VERSION ""

NS_ :

BS_:

BU_: Inverter VCU

BO_ 0 INV_PRIV_NMT: 2 Inverter
 SG_ NodeID  : 8|8@1+ (1,0) [0|255] ""  VCU
 SG_ commmand_specifier  : 0|8@1+ (1,0) [0|255] ""  VCU

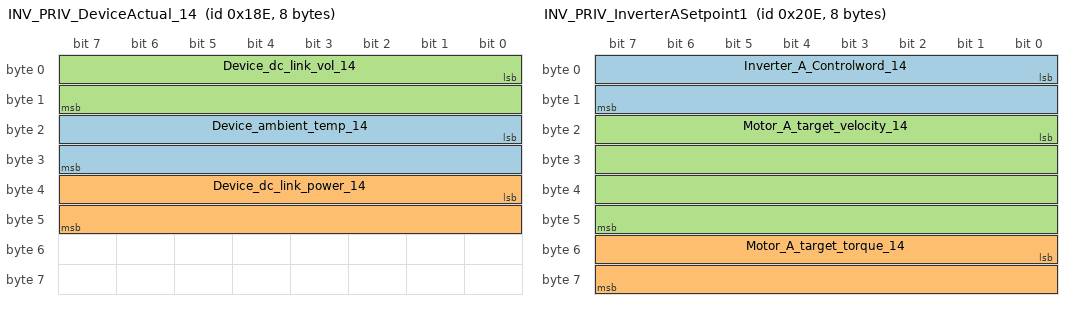
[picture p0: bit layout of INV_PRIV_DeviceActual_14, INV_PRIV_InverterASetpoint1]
BO_ 398 INV_PRIV_DeviceActual_14: 8 Inverter
 SG_ Device_ambient_temp_14  : 16|16@1- (0.0625,0) [-2048|2047.9375] "�C"  VCU
 SG_ Device_dc_link_power_14  : 32|16@1- (0.016,0) [-524.288|524.272] "kW"  VCU
 SG_ Device_dc_link_vol_14  : 0|16@1- (0.0625,0) [-2048|2047.9375] "V"  VCU

BO_ 462 INV_PRIV_InverterAStatus_14: 8 Inverter
 SG_ AMBIENT_OVERTEMPERATURE  : 47|1@1+ (1,0) [0|1] ""  VCU
 SG_ AMBIENT_TEMPERATURE_WARNING  : 46|1@1+ (1,0) [0|1] ""  VCU
 SG_ AMBIENT_TEMPSENSOR_ERROR  : 48|1@1+ (1,0) [0|1] ""  VCU
 SG_ APPC_HAS_GATE_DRIVER_DISABLED  : 44|1@1+ (1,0) [0|1] ""  VCU
 SG_ DCBUS_RIPPLE_TO_HIGH  : 50|1@1+ (1,0) [0|1] ""  VCU
 SG_ DCBUS_SW_OVERVOLTAGE  : 27|1@1+ (1,0) [0|1] ""  VCU
 SG_ DCBUS_SW_UNDERVOLTAGE  : 28|1@1+ (1,0) [0|1] ""  VCU
 SG_ DCBUS_TRIPZONE_OVERVOLTAGE  : 26|1@1+ (1,0) [0|1] ""  VCU
 SG_ EVENTBUFFER_NEW_EVENT  : 16|1@1+ (1,0) [0|1] ""  VCU
 SG_ EVENTBUFFER_OVERFLOW  : 17|1@1+ (1,0) [0|1] ""  VCU
 SG_ INTERLOCK_OPEN  : 43|1@1+ (1,0) [0|1] ""  VCU
 SG_ INVALID_PARAMETER_COMBINATION  : 54|1@1+ (1,0) [0|1] ""  VCU
 SG_ ISOLATION_FAULT  : 58|1@1+ (1,0) [0|1] ""  VCU
 SG_ Inverter_A_Statusword_14  : 0|7@1+ (1,0) [0|127] ""  VCU
 SG_ MOTOR_CONNECTION_TEST_FAILED  : 56|1@1+ (1,0) [0|1] ""  VCU
 SG_ MOTOR_FIELDWEAKENING_ERROR  : 53|1@1+ (1,0) [0|1] ""  VCU
 SG_ MOTOR_I2XT_ERROR  : 52|1@1+ (1,0) [0|1] ""  VCU
 SG_ MOTOR_I2XT_WARNING  : 51|1@1+ (1,0) [0|1] ""  VCU
 SG_ MOTOR_OVERTEMPERATURE  : 32|1@1+ (1,0) [0|1] ""  VCU
 SG_ MOTOR_STALL_ERROR  : 45|1@1+ (1,0) [0|1] ""  VCU
 SG_ MOTOR_STATOR_FREQ_TO_HIGH  : 33|1@1+ (1,0) [0|1] ""  VCU
 SG_ MOTOR_TEMPERATURE_WARNING  : 31|1@1+ (1,0) [0|1] ""  VCU
 SG_ MOTOR_TEMPSENSOR_ERROR  : 30|1@1+ (1,0) [0|1] ""  VCU
 SG_ NEIGHBOUR_FAULT  : 29|1@1+ (1,0) [0|1] ""  VCU
 SG_ NETSYNC_ERROR  : 38|1@1+ (1,0) [0|1] ""  VCU
 SG_ NMT_NOT_OPERATIONAL  : 36|1@1+ (1,0) [0|1] ""  VCU
 SG_ PLUG_COVER_SENSOR_SIGNAL_LOW  : 55|1@1+ (1,0) [0|1] ""  VCU
 SG_ POSDEVICE_SIGNAL_TO_HIGH  : 40|1@1+ (1,0) [0|1] ""  VCU
 SG_ POSDEVICE_SIGNAL_TO_LOW  : 39|1@1+ (1,0) [0|1] ""  VCU
 SG_ POWERMODULE_CLAMPING_TIMEOUT  : 49|1@1+ (1,0) [0|1] ""  VCU
 SG_ POWERMODULE_CURRENT_OFFSET_INI  : 19|1@1+ (1,0) [0|1] ""  VCU
 SG_ POWERMODULE_IXT_FAULT  : 23|1@1+ (1,0) [0|1] ""  VCU
 SG_ POWERMODULE_IXT_WARNING  : 57|1@1+ (1,0) [0|1] ""  VCU
 SG_ POWERMODULE_OVERTEMPERATURE  : 22|1@1+ (1,0) [0|1] ""  VCU
 SG_ POWERMODULE_PATTERNDATA_INCONS  : 25|1@1+ (1,0) [0|1] ""  VCU
 SG_ POWERMODULE_SW_OVERCURRENT  : 24|1@1+ (1,0) [0|1] ""  VCU
 SG_ POWERMODULE_TEMPERATURE_WARNIN  : 21|1@1+ (1,0) [0|1] ""  VCU
 SG_ POWERMODULE_TEMPSENSOR_ERROR  : 20|1@1+ (1,0) [0|1] ""  VCU
 SG_ POWERMODULE_TRIPZONE_OVERCURRE  : 18|1@1+ (1,0) [0|1] ""  VCU
 SG_ RESOLVER_CALIBRATION_FAILED  : 41|1@1+ (1,0) [0|1] ""  VCU
 SG_ RPDO_TIMEOUT  : 35|1@1+ (1,0) [0|1] ""  VCU
 SG_ SUPPLYVOLTAGE_ERROR  : 34|1@1+ (1,0) [0|1] ""  VCU
 SG_ SYSTEM_FAULT  : 42|1@1+ (1,0) [0|1] ""  VCU
 SG_ TASKOVERRUN  : 37|1@1+ (1,0) [0|1] ""  VCU

BO_ 526 INV_PRIV_InverterASetpoint1: 8 VCU
 SG_ Inverter_A_Controlword_14  : 0|16@1+ (1,0) [0|65535] ""  Inverter
 SG_ Motor_A_target_torque_14  : 48|16@1- (0.1,0) [-3276.8|3276.7] "%"  Inverter
 SG_ Motor_A_target_velocity_14  : 16|32@1- (6.103515625e-05,0) [-131072|131071.9999389648] "rpm"  Inverter

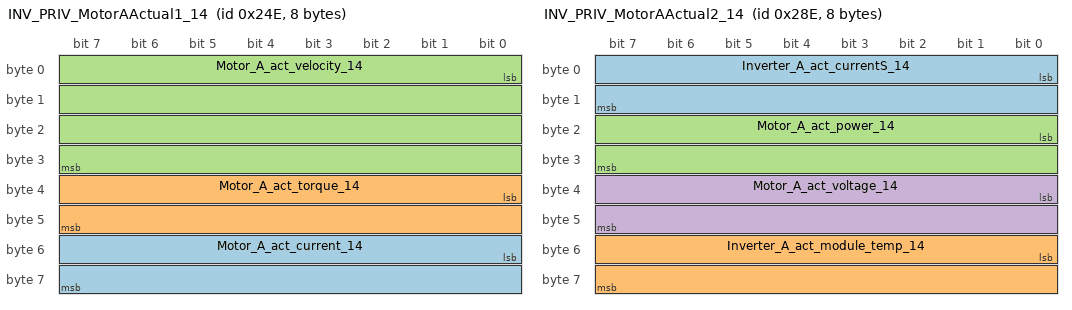
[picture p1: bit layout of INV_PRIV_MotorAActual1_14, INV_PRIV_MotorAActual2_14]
BO_ 590 INV_PRIV_MotorAActual1_14: 8 Inverter
 SG_ Motor_A_act_current_14  : 48|16@1- (0.015625,0) [-512|511.984375] "A"  VCU
 SG_ Motor_A_act_torque_14  : 32|16@1- (0.1,0) [-3276.8|3276.7] "%"  VCU
 SG_ Motor_A_act_velocity_14  : 0|32@1- (6.103515625e-05,0) [-131072|131071.9999389648] "rpm"  VCU

BO_ 654 INV_PRIV_MotorAActual2_14: 8 Inverter
 SG_ Inverter_A_act_currentS_14  : 0|16@1- (0.015625,0) [-512|511.984375] "A"  VCU
 SG_ Inverter_A_act_module_temp_14  : 48|16@1- (0.0625,0) [-2048|2047.9375] "�C"  VCU
 SG_ Motor_A_act_power_14  : 16|16@1- (0.016,0) [-524.288|524.272] "kW"  VCU
 SG_ Motor_A_act_voltage_14  : 32|16@1- (0.0625,0) [-2048|2047.9375] "V"  VCU

BO_ 718 INV_PRIV_InverterBStatus_14: 8 Inverter
 SG_ AMBIENT_OVERTEMPERATURE  : 47|1@1+ (1,0) [0|1] ""  VCU
 SG_ AMBIENT_TEMPERATURE_WARNING  : 46|1@1+ (1,0) [0|1] ""  VCU
 SG_ AMBIENT_TEMPSENSOR_ERROR  : 48|1@1+ (1,0) [0|1] ""  VCU
 SG_ APPC_HAS_GATE_DRIVER_DISABLED  : 44|1@1+ (1,0) [0|1] ""  VCU
 SG_ DCBUS_RIPPLE_TO_HIGH  : 50|1@1+ (1,0) [0|1] ""  VCU
 SG_ DCBUS_SW_OVERVOLTAGE  : 27|1@1+ (1,0) [0|1] ""  VCU
 SG_ DCBUS_SW_UNDERVOLTAGE  : 28|1@1+ (1,0) [0|1] ""  VCU
 SG_ DCBUS_TRIPZONE_OVERVOLTAGE  : 26|1@1+ (1,0) [0|1] ""  VCU
 SG_ EVENTBUFFER_NEW_EVENT  : 16|1@1+ (1,0) [0|1] ""  VCU
 SG_ EVENTBUFFER_OVERFLOW  : 17|1@1+ (1,0) [0|1] ""  VCU
 SG_ INTERLOCK_OPEN  : 43|1@1+ (1,0) [0|1] ""  VCU
 SG_ INVALID_PARAMETER_COMBINATION  : 54|1@1+ (1,0) [0|1] ""  VCU
 SG_ ISOLATION_FAULT  : 58|1@1+ (1,0) [0|1] ""  VCU
 SG_ Inverter_B_Statusword_14  : 0|7@1+ (1,0) [0|127] ""  VCU
 SG_ MOTOR_CONNECTION_TEST_FAILED  : 56|1@1+ (1,0) [0|1] ""  VCU
 SG_ MOTOR_FIELDWEAKENING_ERROR  : 53|1@1+ (1,0) [0|1] ""  VCU
 SG_ MOTOR_I2XT_ERROR  : 52|1@1+ (1,0) [0|1] ""  VCU
 SG_ MOTOR_I2XT_WARNING  : 51|1@1+ (1,0) [0|1] ""  VCU
 SG_ MOTOR_OVERTEMPERATURE  : 32|1@1+ (1,0) [0|1] ""  VCU
 SG_ MOTOR_STALL_ERROR  : 45|1@1+ (1,0) [0|1] ""  VCU
 SG_ MOTOR_STATOR_FREQ_TO_HIGH  : 33|1@1+ (1,0) [0|1] ""  VCU
 SG_ MOTOR_TEMPERATURE_WARNING  : 31|1@1+ (1,0) [0|1] ""  VCU
 SG_ MOTOR_TEMPSENSOR_ERROR  : 30|1@1+ (1,0) [0|1] ""  VCU
 SG_ NEIGHBOUR_FAULT  : 29|1@1+ (1,0) [0|1] ""  VCU
 SG_ NETSYNC_ERROR  : 38|1@1+ (1,0) [0|1] ""  VCU
 SG_ NMT_NOT_OPERATIONAL  : 36|1@1+ (1,0) [0|1] ""  VCU
 SG_ PLUG_COVER_SENSOR_SIGNAL_LOW  : 55|1@1+ (1,0) [0|1] ""  VCU
 SG_ POSDEVICE_SIGNAL_TO_HIGH  : 40|1@1+ (1,0) [0|1] ""  VCU
 SG_ POSDEVICE_SIGNAL_TO_LOW  : 39|1@1+ (1,0) [0|1] ""  VCU
 SG_ POWERMODULE_CLAMPING_TIMEOUT  : 49|1@1+ (1,0) [0|1] ""  VCU
 SG_ POWERMODULE_CURRENT_OFFSET_INI  : 19|1@1+ (1,0) [0|1] ""  VCU
 SG_ POWERMODULE_IXT_FAULT  : 23|1@1+ (1,0) [0|1] ""  VCU
 SG_ POWERMODULE_IXT_WARNING  : 57|1@1+ (1,0) [0|1] ""  VCU
 SG_ POWERMODULE_OVERTEMPERATURE  : 22|1@1+ (1,0) [0|1] ""  VCU
 SG_ POWERMODULE_PATTERNDATA_INCONS  : 25|1@1+ (1,0) [0|1] ""  VCU
 SG_ POWERMODULE_SW_OVERCURRENT  : 24|1@1+ (1,0) [0|1] ""  VCU
 SG_ POWERMODULE_TEMPERATURE_WARNIN  : 21|1@1+ (1,0) [0|1] ""  VCU
 SG_ POWERMODULE_TEMPSENSOR_ERROR  : 20|1@1+ (1,0) [0|1] ""  VCU
 SG_ POWERMODULE_TRIPZONE_OVERCURRE  : 18|1@1+ (1,0) [0|1] ""  VCU
 SG_ RESOLVER_CALIBRATION_FAILED  : 41|1@1+ (1,0) [0|1] ""  VCU
 SG_ RPDO_TIMEOUT  : 35|1@1+ (1,0) [0|1] ""  VCU
 SG_ SUPPLYVOLTAGE_ERROR  : 34|1@1+ (1,0) [0|1] ""  VCU
 SG_ SYSTEM_FAULT  : 42|1@1+ (1,0) [0|1] ""  VCU
 SG_ TASKOVERRUN  : 37|1@1+ (1,0) [0|1] ""  VCU

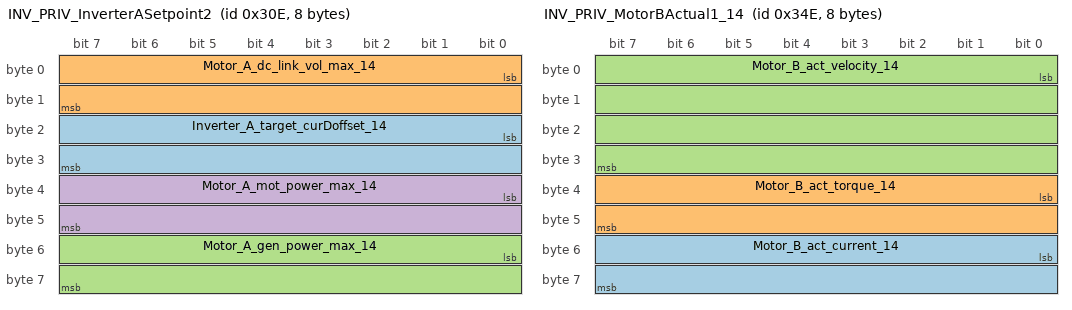
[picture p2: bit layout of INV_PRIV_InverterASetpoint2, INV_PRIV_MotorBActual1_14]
BO_ 782 INV_PRIV_InverterASetpoint2: 8 VCU
 SG_ Inverter_A_target_curDoffset_14  : 16|16@1- (0.015625,0) [-512|511.984375] "A"  Inverter
 SG_ Motor_A_dc_link_vol_max_14  : 0|16@1- (0.0625,0) [-2048|2047.9375] "V"  Inverter
 SG_ Motor_A_gen_power_max_14  : 48|16@1- (0.1,0) [-3276.8|3276.7] "%"  Inverter
 SG_ Motor_A_mot_power_max_14  : 32|16@1- (0.1,0) [-3276.8|3276.7] "%"  Inverter

BO_ 846 INV_PRIV_MotorBActual1_14: 8 Inverter
 SG_ Motor_B_act_current_14  : 48|16@1- (0.015625,0) [-512|511.984375] "A"  VCU
 SG_ Motor_B_act_torque_14  : 32|16@1- (0.1,0) [-3276.8|3276.7] "%"  VCU
 SG_ Motor_B_act_velocity_14  : 0|32@1- (6.103515625e-05,0) [-131072|131071.9999389648] "rpm"  VCU

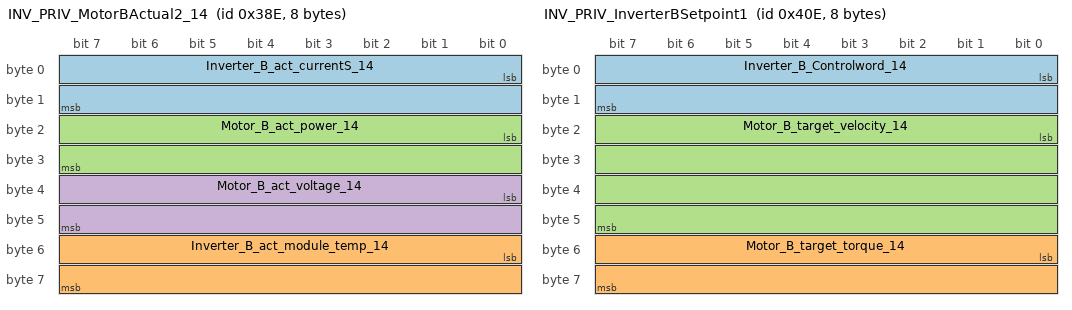
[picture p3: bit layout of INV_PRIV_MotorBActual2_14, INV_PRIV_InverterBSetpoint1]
BO_ 910 INV_PRIV_MotorBActual2_14: 8 Inverter
 SG_ Inverter_B_act_currentS_14  : 0|16@1- (0.015625,0) [-512|511.984375] "A"  VCU
 SG_ Inverter_B_act_module_temp_14  : 48|16@1- (0.0625,0) [-2048|2047.9375] "�C"  VCU
 SG_ Motor_B_act_power_14  : 16|16@1- (0.016,0) [-524.288|524.272] "kW"  VCU
 SG_ Motor_B_act_voltage_14  : 32|16@1- (0.0625,0) [-2048|2047.9375] "V"  VCU

BO_ 1038 INV_PRIV_InverterBSetpoint1: 8 VCU
 SG_ Inverter_B_Controlword_14  : 0|16@1+ (1,0) [0|65535] ""  Inverter
 SG_ Motor_B_target_torque_14  : 48|16@1- (0.1,0) [-3276.8|3276.7] "%"  Inverter
 SG_ Motor_B_target_velocity_14  : 16|32@1- (6.103515625e-05,0) [-131072|131071.9999389648] "rpm"  Inverter

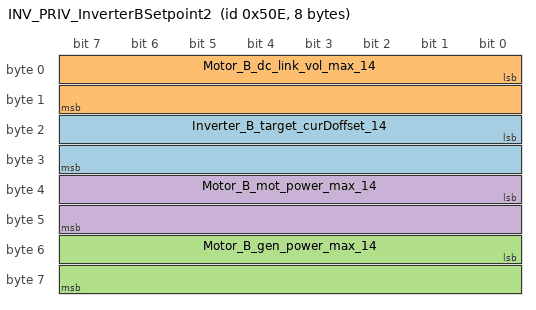
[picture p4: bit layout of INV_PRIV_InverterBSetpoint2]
BO_ 1294 INV_PRIV_InverterBSetpoint2: 8 VCU
 SG_ Inverter_B_target_curDoffset_14  : 16|16@1- (0.015625,0) [-512|511.984375] "A"  Inverter
 SG_ Motor_B_dc_link_vol_max_14  : 0|16@1- (0.0625,0) [-2048|2047.9375] "V"  Inverter
 SG_ Motor_B_gen_power_max_14  : 48|16@1- (0.1,0) [-3276.8|3276.7] "%"  Inverter
 SG_ Motor_B_mot_power_max_14  : 32|16@1- (0.1,0) [-3276.8|3276.7] "%"  Inverter

BO_ 1358 INV_PRIV_DeviceSetpoint_14: 8 VCU
 SG_ dc_link_vol_precharge_dmd_14  : 32|16@1- (0.0625,0) [-2048|2047.9375] "V"  Inverter
 SG_ system_time_stamp_14  : 0|32@1+ (1,0) [0|4294967295] "ms"  Inverter

CM_ BO_ 526 "Original name (from import source): INV_R_PRIV_InverterASetpoint1_14";
CM_ BO_ 782 "Original name (from import source): INV_R_PRIV_InverterASetpoint2_14";
CM_ BO_ 1038 "Original name (from import source): INV_R_PRIV_InverterBSetpoint1_14";
CM_ BO_ 1294 "Original name (from import source): INV_R_PRIV_InverterBSetpoint2_14";
BA_DEF_  "DBName" STRING ;
BA_DEF_ BO_  "GenMsgSendType" ENUM  "Cyclic","OnEvent";
BA_DEF_ SG_  "GenSigSendType" ENUM  "NoSigSendType";
BA_DEF_ SG_  "GenSigStartValue" INT 0 0;
BA_DEF_ SG_  "SPN" INT 0 524287;
BA_DEF_DEF_  "DBName" "";
BA_DEF_DEF_  "GenMsgSendType" "NoMsgSendType";
BA_DEF_DEF_  "GenSigSendType" "Cyclic";
BA_DEF_DEF_  "SPN" 0;
BA_ "DBName" "CAN4";
BA_ "GenMsgSendType" BO_ 0 1;
BA_ "GenMsgSendType" BO_ 398 1;
BA_ "GenMsgSendType" BO_ 462 1;
BA_ "GenMsgSendType" BO_ 526 1;
BA_ "GenMsgSendType" BO_ 590 1;
BA_ "GenMsgSendType" BO_ 654 1;
BA_ "GenMsgSendType" BO_ 718 1;
BA_ "GenMsgSendType" BO_ 782 1;
BA_ "GenMsgSendType" BO_ 846 1;
BA_ "GenMsgSendType" BO_ 910 1;
BA_ "GenMsgSendType" BO_ 1038 1;
BA_ "GenMsgSendType" BO_ 1294 1;
BA_ "GenMsgSendType" BO_ 1358 1;
BA_ "GenSigStartValue" SG_ 0 NodeID 0;
BA_ "GenSigStartValue" SG_ 0 commmand_specifier 0;
BA_ "GenSigStartValue" SG_ 398 Device_ambient_temp_14 0;
BA_ "GenSigStartValue" SG_ 398 Device_dc_link_power_14 0;
BA_ "GenSigStartValue" SG_ 398 Device_dc_link_vol_14 0;
BA_ "GenSigStartValue" SG_ 462 AMBIENT_OVERTEMPERATURE 0;
BA_ "GenSigStartValue" SG_ 462 AMBIENT_TEMPERATURE_WARNING 0;
BA_ "GenSigStartValue" SG_ 462 AMBIENT_TEMPSENSOR_ERROR 0;
BA_ "GenSigStartValue" SG_ 462 APPC_HAS_GATE_DRIVER_DISABLED 0;
BA_ "GenSigStartValue" SG_ 462 DCBUS_RIPPLE_TO_HIGH 0;
BA_ "GenSigStartValue" SG_ 462 DCBUS_SW_OVERVOLTAGE 0;
BA_ "GenSigStartValue" SG_ 462 DCBUS_SW_UNDERVOLTAGE 0;
BA_ "GenSigStartValue" SG_ 462 DCBUS_TRIPZONE_OVERVOLTAGE 0;
BA_ "GenSigStartValue" SG_ 462 EVENTBUFFER_NEW_EVENT 0;
BA_ "GenSigStartValue" SG_ 462 EVENTBUFFER_OVERFLOW 0;
BA_ "GenSigStartValue" SG_ 462 INTERLOCK_OPEN 0;
BA_ "GenSigStartValue" SG_ 462 INVALID_PARAMETER_COMBINATION 0;
BA_ "GenSigStartValue" SG_ 462 ISOLATION_FAULT 0;
BA_ "GenSigStartValue" SG_ 462 Inverter_A_Statusword_14 0;
BA_ "GenSigStartValue" SG_ 462 MOTOR_CONNECTION_TEST_FAILED 0;
BA_ "GenSigStartValue" SG_ 462 MOTOR_FIELDWEAKENING_ERROR 0;
BA_ "GenSigStartValue" SG_ 462 MOTOR_I2XT_ERROR 0;
BA_ "GenSigStartValue" SG_ 462 MOTOR_I2XT_WARNING 0;
BA_ "GenSigStartValue" SG_ 462 MOTOR_OVERTEMPERATURE 0;
BA_ "GenSigStartValue" SG_ 462 MOTOR_STALL_ERROR 0;
BA_ "GenSigStartValue" SG_ 462 MOTOR_STATOR_FREQ_TO_HIGH 0;
BA_ "GenSigStartValue" SG_ 462 MOTOR_TEMPERATURE_WARNING 0;
BA_ "GenSigStartValue" SG_ 462 MOTOR_TEMPSENSOR_ERROR 0;
BA_ "GenSigStartValue" SG_ 462 NEIGHBOUR_FAULT 0;
BA_ "GenSigStartValue" SG_ 462 NETSYNC_ERROR 0;
BA_ "GenSigStartValue" SG_ 462 NMT_NOT_OPERATIONAL 0;
BA_ "GenSigStartValue" SG_ 462 PLUG_COVER_SENSOR_SIGNAL_LOW 0;
BA_ "GenSigStartValue" SG_ 462 POSDEVICE_SIGNAL_TO_HIGH 0;
BA_ "GenSigStartValue" SG_ 462 POSDEVICE_SIGNAL_TO_LOW 0;
BA_ "GenSigStartValue" SG_ 462 POWERMODULE_CLAMPING_TIMEOUT 0;
BA_ "GenSigStartValue" SG_ 462 POWERMODULE_CURRENT_OFFSET_INI 0;
BA_ "GenSigStartValue" SG_ 462 POWERMODULE_IXT_FAULT 0;
BA_ "GenSigStartValue" SG_ 462 POWERMODULE_IXT_WARNING 0;
BA_ "GenSigStartValue" SG_ 462 POWERMODULE_OVERTEMPERATURE 0;
BA_ "GenSigStartValue" SG_ 462 POWERMODULE_PATTERNDATA_INCONS 0;
BA_ "GenSigStartValue" SG_ 462 POWERMODULE_SW_OVERCURRENT 0;
BA_ "GenSigStartValue" SG_ 462 POWERMODULE_TEMPERATURE_WARNIN 0;
BA_ "GenSigStartValue" SG_ 462 POWERMODULE_TEMPSENSOR_ERROR 0;
BA_ "GenSigStartValue" SG_ 462 POWERMODULE_TRIPZONE_OVERCURRE 0;
BA_ "GenSigStartValue" SG_ 462 RESOLVER_CALIBRATION_FAILED 0;
BA_ "GenSigStartValue" SG_ 462 RPDO_TIMEOUT 0;
BA_ "GenSigStartValue" SG_ 462 SUPPLYVOLTAGE_ERROR 0;
BA_ "GenSigStartValue" SG_ 462 SYSTEM_FAULT 0;
BA_ "GenSigStartValue" SG_ 462 TASKOVERRUN 0;
BA_ "GenSigStartValue" SG_ 526 Inverter_A_Controlword_14 0;
BA_ "GenSigStartValue" SG_ 526 Motor_A_target_torque_14 0;
BA_ "GenSigStartValue" SG_ 526 Motor_A_target_velocity_14 0;
BA_ "GenSigStartValue" SG_ 590 Motor_A_act_current_14 0;
BA_ "GenSigStartValue" SG_ 590 Motor_A_act_torque_14 0;
BA_ "GenSigStartValue" SG_ 590 Motor_A_act_velocity_14 0;
BA_ "GenSigStartValue" SG_ 654 Inverter_A_act_currentS_14 0;
BA_ "GenSigStartValue" SG_ 654 Inverter_A_act_module_temp_14 0;
BA_ "GenSigStartValue" SG_ 654 Motor_A_act_power_14 0;
BA_ "GenSigStartValue" SG_ 654 Motor_A_act_voltage_14 0;
BA_ "GenSigStartValue" SG_ 718 AMBIENT_OVERTEMPERATURE 0;
BA_ "GenSigStartValue" SG_ 718 AMBIENT_TEMPERATURE_WARNING 0;
BA_ "GenSigStartValue" SG_ 718 AMBIENT_TEMPSENSOR_ERROR 0;
BA_ "GenSigStartValue" SG_ 718 APPC_HAS_GATE_DRIVER_DISABLED 0;
BA_ "GenSigStartValue" SG_ 718 DCBUS_RIPPLE_TO_HIGH 0;
BA_ "GenSigStartValue" SG_ 718 DCBUS_SW_OVERVOLTAGE 0;
BA_ "GenSigStartValue" SG_ 718 DCBUS_SW_UNDERVOLTAGE 0;
BA_ "GenSigStartValue" SG_ 718 DCBUS_TRIPZONE_OVERVOLTAGE 0;
BA_ "GenSigStartValue" SG_ 718 EVENTBUFFER_NEW_EVENT 0;
BA_ "GenSigStartValue" SG_ 718 EVENTBUFFER_OVERFLOW 0;
BA_ "GenSigStartValue" SG_ 718 INTERLOCK_OPEN 0;
BA_ "GenSigStartValue" SG_ 718 INVALID_PARAMETER_COMBINATION 0;
BA_ "GenSigStartValue" SG_ 718 ISOLATION_FAULT 0;
BA_ "GenSigStartValue" SG_ 718 Inverter_B_Statusword_14 0;
BA_ "GenSigStartValue" SG_ 718 MOTOR_CONNECTION_TEST_FAILED 0;
BA_ "GenSigStartValue" SG_ 718 MOTOR_FIELDWEAKENING_ERROR 0;
BA_ "GenSigStartValue" SG_ 718 MOTOR_I2XT_ERROR 0;
BA_ "GenSigStartValue" SG_ 718 MOTOR_I2XT_WARNING 0;
BA_ "GenSigStartValue" SG_ 718 MOTOR_OVERTEMPERATURE 0;
BA_ "GenSigStartValue" SG_ 718 MOTOR_STALL_ERROR 0;
BA_ "GenSigStartValue" SG_ 718 MOTOR_STATOR_FREQ_TO_HIGH 0;
BA_ "GenSigStartValue" SG_ 718 MOTOR_TEMPERATURE_WARNING 0;
BA_ "GenSigStartValue" SG_ 718 MOTOR_TEMPSENSOR_ERROR 0;
BA_ "GenSigStartValue" SG_ 718 NEIGHBOUR_FAULT 0;
BA_ "GenSigStartValue" SG_ 718 NETSYNC_ERROR 0;
BA_ "GenSigStartValue" SG_ 718 NMT_NOT_OPERATIONAL 0;
BA_ "GenSigStartValue" SG_ 718 PLUG_COVER_SENSOR_SIGNAL_LOW 0;
BA_ "GenSigStartValue" SG_ 718 POSDEVICE_SIGNAL_TO_HIGH 0;
BA_ "GenSigStartValue" SG_ 718 POSDEVICE_SIGNAL_TO_LOW 0;
BA_ "GenSigStartValue" SG_ 718 POWERMODULE_CLAMPING_TIMEOUT 0;
BA_ "GenSigStartValue" SG_ 718 POWERMODULE_CURRENT_OFFSET_INI 0;
BA_ "GenSigStartValue" SG_ 718 POWERMODULE_IXT_FAULT 0;
BA_ "GenSigStartValue" SG_ 718 POWERMODULE_IXT_WARNING 0;
BA_ "GenSigStartValue" SG_ 718 POWERMODULE_OVERTEMPERATURE 0;
BA_ "GenSigStartValue" SG_ 718 POWERMODULE_PATTERNDATA_INCONS 0;
BA_ "GenSigStartValue" SG_ 718 POWERMODULE_SW_OVERCURRENT 0;
BA_ "GenSigStartValue" SG_ 718 POWERMODULE_TEMPERATURE_WARNIN 0;
BA_ "GenSigStartValue" SG_ 718 POWERMODULE_TEMPSENSOR_ERROR 0;
BA_ "GenSigStartValue" SG_ 718 POWERMODULE_TRIPZONE_OVERCURRE 0;
BA_ "GenSigStartValue" SG_ 718 RESOLVER_CALIBRATION_FAILED 0;
BA_ "GenSigStartValue" SG_ 718 RPDO_TIMEOUT 0;
BA_ "GenSigStartValue" SG_ 718 SUPPLYVOLTAGE_ERROR 0;
BA_ "GenSigStartValue" SG_ 718 SYSTEM_FAULT 0;
BA_ "GenSigStartValue" SG_ 718 TASKOVERRUN 0;
BA_ "GenSigStartValue" SG_ 782 Inverter_A_target_curDoffset_14 0;
BA_ "GenSigStartValue" SG_ 782 Motor_A_dc_link_vol_max_14 0;
BA_ "GenSigStartValue" SG_ 782 Motor_A_gen_power_max_14 0;
BA_ "GenSigStartValue" SG_ 782 Motor_A_mot_power_max_14 0;
BA_ "GenSigStartValue" SG_ 846 Motor_B_act_current_14 0;
BA_ "GenSigStartValue" SG_ 846 Motor_B_act_torque_14 0;
BA_ "GenSigStartValue" SG_ 846 Motor_B_act_velocity_14 0;
BA_ "GenSigStartValue" SG_ 910 Inverter_B_act_currentS_14 0;
BA_ "GenSigStartValue" SG_ 910 Inverter_B_act_module_temp_14 0;
BA_ "GenSigStartValue" SG_ 910 Motor_B_act_power_14 0;
BA_ "GenSigStartValue" SG_ 910 Motor_B_act_voltage_14 0;
BA_ "GenSigStartValue" SG_ 1038 Inverter_B_Controlword_14 0;
BA_ "GenSigStartValue" SG_ 1038 Motor_B_target_torque_14 0;
BA_ "GenSigStartValue" SG_ 1038 Motor_B_target_velocity_14 0;
BA_ "GenSigStartValue" SG_ 1294 Inverter_B_target_curDoffset_14 0;
BA_ "GenSigStartValue" SG_ 1294 Motor_B_dc_link_vol_max_14 0;
BA_ "GenSigStartValue" SG_ 1294 Motor_B_gen_power_max_14 0;
BA_ "GenSigStartValue" SG_ 1294 Motor_B_mot_power_max_14 0;
BA_ "GenSigStartValue" SG_ 1358 dc_link_vol_precharge_dmd_14 0;
BA_ "GenSigStartValue" SG_ 1358 system_time_stamp_14 0;
SIG_VALTYPE_ 0 NodeID : 0;
SIG_VALTYPE_ 0 commmand_specifier : 0;
SIG_VALTYPE_ 398 Device_ambient_temp_14 : 0;
SIG_VALTYPE_ 398 Device_dc_link_power_14 : 0;
SIG_VALTYPE_ 398 Device_dc_link_vol_14 : 0;
SIG_VALTYPE_ 462 AMBIENT_OVERTEMPERATURE : 0;
SIG_VALTYPE_ 462 AMBIENT_TEMPERATURE_WARNING : 0;
SIG_VALTYPE_ 462 AMBIENT_TEMPSENSOR_ERROR : 0;
SIG_VALTYPE_ 462 APPC_HAS_GATE_DRIVER_DISABLED : 0;
SIG_VALTYPE_ 462 DCBUS_RIPPLE_TO_HIGH : 0;
SIG_VALTYPE_ 462 DCBUS_SW_OVERVOLTAGE : 0;
SIG_VALTYPE_ 462 DCBUS_SW_UNDERVOLTAGE : 0;
SIG_VALTYPE_ 462 DCBUS_TRIPZONE_OVERVOLTAGE : 0;
SIG_VALTYPE_ 462 EVENTBUFFER_NEW_EVENT : 0;
SIG_VALTYPE_ 462 EVENTBUFFER_OVERFLOW : 0;
SIG_VALTYPE_ 462 INTERLOCK_OPEN : 0;
SIG_VALTYPE_ 462 INVALID_PARAMETER_COMBINATION : 0;
SIG_VALTYPE_ 462 ISOLATION_FAULT : 0;
SIG_VALTYPE_ 462 Inverter_A_Statusword_14 : 0;
SIG_VALTYPE_ 462 MOTOR_CONNECTION_TEST_FAILED : 0;
SIG_VALTYPE_ 462 MOTOR_FIELDWEAKENING_ERROR : 0;
SIG_VALTYPE_ 462 MOTOR_I2XT_ERROR : 0;
SIG_VALTYPE_ 462 MOTOR_I2XT_WARNING : 0;
SIG_VALTYPE_ 462 MOTOR_OVERTEMPERATURE : 0;
SIG_VALTYPE_ 462 MOTOR_STALL_ERROR : 0;
SIG_VALTYPE_ 462 MOTOR_STATOR_FREQ_TO_HIGH : 0;
SIG_VALTYPE_ 462 MOTOR_TEMPERATURE_WARNING : 0;
SIG_VALTYPE_ 462 MOTOR_TEMPSENSOR_ERROR : 0;
SIG_VALTYPE_ 462 NEIGHBOUR_FAULT : 0;
SIG_VALTYPE_ 462 NETSYNC_ERROR : 0;
SIG_VALTYPE_ 462 NMT_NOT_OPERATIONAL : 0;
SIG_VALTYPE_ 462 PLUG_COVER_SENSOR_SIGNAL_LOW : 0;
SIG_VALTYPE_ 462 POSDEVICE_SIGNAL_TO_HIGH : 0;
SIG_VALTYPE_ 462 POSDEVICE_SIGNAL_TO_LOW : 0;
SIG_VALTYPE_ 462 POWERMODULE_CLAMPING_TIMEOUT : 0;
SIG_VALTYPE_ 462 POWERMODULE_CURRENT_OFFSET_INI : 0;
SIG_VALTYPE_ 462 POWERMODULE_IXT_FAULT : 0;
SIG_VALTYPE_ 462 POWERMODULE_IXT_WARNING : 0;
SIG_VALTYPE_ 462 POWERMODULE_OVERTEMPERATURE : 0;
SIG_VALTYPE_ 462 POWERMODULE_PATTERNDATA_INCONS : 0;
SIG_VALTYPE_ 462 POWERMODULE_SW_OVERCURRENT : 0;
SIG_VALTYPE_ 462 POWERMODULE_TEMPERATURE_WARNIN : 0;
SIG_VALTYPE_ 462 POWERMODULE_TEMPSENSOR_ERROR : 0;
SIG_VALTYPE_ 462 POWERMODULE_TRIPZONE_OVERCURRE : 0;
SIG_VALTYPE_ 462 RESOLVER_CALIBRATION_FAILED : 0;
SIG_VALTYPE_ 462 RPDO_TIMEOUT : 0;
SIG_VALTYPE_ 462 SUPPLYVOLTAGE_ERROR : 0;
SIG_VALTYPE_ 462 SYSTEM_FAULT : 0;
SIG_VALTYPE_ 462 TASKOVERRUN : 0;
SIG_VALTYPE_ 526 Inverter_A_Controlword_14 : 0;
SIG_VALTYPE_ 526 Motor_A_target_torque_14 : 0;
SIG_VALTYPE_ 526 Motor_A_target_velocity_14 : 0;
SIG_VALTYPE_ 590 Motor_A_act_current_14 : 0;
SIG_VALTYPE_ 590 Motor_A_act_torque_14 : 0;
SIG_VALTYPE_ 590 Motor_A_act_velocity_14 : 0;
SIG_VALTYPE_ 654 Inverter_A_act_currentS_14 : 0;
SIG_VALTYPE_ 654 Inverter_A_act_module_temp_14 : 0;
SIG_VALTYPE_ 654 Motor_A_act_power_14 : 0;
SIG_VALTYPE_ 654 Motor_A_act_voltage_14 : 0;
SIG_VALTYPE_ 718 AMBIENT_OVERTEMPERATURE : 0;
SIG_VALTYPE_ 718 AMBIENT_TEMPERATURE_WARNING : 0;
SIG_VALTYPE_ 718 AMBIENT_TEMPSENSOR_ERROR : 0;
SIG_VALTYPE_ 718 APPC_HAS_GATE_DRIVER_DISABLED : 0;
SIG_VALTYPE_ 718 DCBUS_RIPPLE_TO_HIGH : 0;
SIG_VALTYPE_ 718 DCBUS_SW_OVERVOLTAGE : 0;
SIG_VALTYPE_ 718 DCBUS_SW_UNDERVOLTAGE : 0;
SIG_VALTYPE_ 718 DCBUS_TRIPZONE_OVERVOLTAGE : 0;
SIG_VALTYPE_ 718 EVENTBUFFER_NEW_EVENT : 0;
SIG_VALTYPE_ 718 EVENTBUFFER_OVERFLOW : 0;
SIG_VALTYPE_ 718 INTERLOCK_OPEN : 0;
SIG_VALTYPE_ 718 INVALID_PARAMETER_COMBINATION : 0;
SIG_VALTYPE_ 718 ISOLATION_FAULT : 0;
SIG_VALTYPE_ 718 Inverter_B_Statusword_14 : 0;
SIG_VALTYPE_ 718 MOTOR_CONNECTION_TEST_FAILED : 0;
SIG_VALTYPE_ 718 MOTOR_FIELDWEAKENING_ERROR : 0;
SIG_VALTYPE_ 718 MOTOR_I2XT_ERROR : 0;
SIG_VALTYPE_ 718 MOTOR_I2XT_WARNING : 0;
SIG_VALTYPE_ 718 MOTOR_OVERTEMPERATURE : 0;
SIG_VALTYPE_ 718 MOTOR_STALL_ERROR : 0;
SIG_VALTYPE_ 718 MOTOR_STATOR_FREQ_TO_HIGH : 0;
SIG_VALTYPE_ 718 MOTOR_TEMPERATURE_WARNING : 0;
SIG_VALTYPE_ 718 MOTOR_TEMPSENSOR_ERROR : 0;
SIG_VALTYPE_ 718 NEIGHBOUR_FAULT : 0;
SIG_VALTYPE_ 718 NETSYNC_ERROR : 0;
SIG_VALTYPE_ 718 NMT_NOT_OPERATIONAL : 0;
SIG_VALTYPE_ 718 PLUG_COVER_SENSOR_SIGNAL_LOW : 0;
SIG_VALTYPE_ 718 POSDEVICE_SIGNAL_TO_HIGH : 0;
SIG_VALTYPE_ 718 POSDEVICE_SIGNAL_TO_LOW : 0;
SIG_VALTYPE_ 718 POWERMODULE_CLAMPING_TIMEOUT : 0;
SIG_VALTYPE_ 718 POWERMODULE_CURRENT_OFFSET_INI : 0;
SIG_VALTYPE_ 718 POWERMODULE_IXT_FAULT : 0;
SIG_VALTYPE_ 718 POWERMODULE_IXT_WARNING : 0;
SIG_VALTYPE_ 718 POWERMODULE_OVERTEMPERATURE : 0;
SIG_VALTYPE_ 718 POWERMODULE_PATTERNDATA_INCONS : 0;
SIG_VALTYPE_ 718 POWERMODULE_SW_OVERCURRENT : 0;
SIG_VALTYPE_ 718 POWERMODULE_TEMPERATURE_WARNIN : 0;
SIG_VALTYPE_ 718 POWERMODULE_TEMPSENSOR_ERROR : 0;
SIG_VALTYPE_ 718 POWERMODULE_TRIPZONE_OVERCURRE : 0;
SIG_VALTYPE_ 718 RESOLVER_CALIBRATION_FAILED : 0;
SIG_VALTYPE_ 718 RPDO_TIMEOUT : 0;
SIG_VALTYPE_ 718 SUPPLYVOLTAGE_ERROR : 0;
SIG_VALTYPE_ 718 SYSTEM_FAULT : 0;
SIG_VALTYPE_ 718 TASKOVERRUN : 0;
SIG_VALTYPE_ 782 Inverter_A_target_curDoffset_14 : 0;
SIG_VALTYPE_ 782 Motor_A_dc_link_vol_max_14 : 0;
SIG_VALTYPE_ 782 Motor_A_gen_power_max_14 : 0;
SIG_VALTYPE_ 782 Motor_A_mot_power_max_14 : 0;
SIG_VALTYPE_ 846 Motor_B_act_current_14 : 0;
SIG_VALTYPE_ 846 Motor_B_act_torque_14 : 0;
SIG_VALTYPE_ 846 Motor_B_act_velocity_14 : 0;
SIG_VALTYPE_ 910 Inverter_B_act_currentS_14 : 0;
SIG_VALTYPE_ 910 Inverter_B_act_module_temp_14 : 0;
SIG_VALTYPE_ 910 Motor_B_act_power_14 : 0;
SIG_VALTYPE_ 910 Motor_B_act_voltage_14 : 0;
SIG_VALTYPE_ 1038 Inverter_B_Controlword_14 : 0;
SIG_VALTYPE_ 1038 Motor_B_target_torque_14 : 0;
SIG_VALTYPE_ 1038 Motor_B_target_velocity_14 : 0;
SIG_VALTYPE_ 1294 Inverter_B_target_curDoffset_14 : 0;
SIG_VALTYPE_ 1294 Motor_B_dc_link_vol_max_14 : 0;
SIG_VALTYPE_ 1294 Motor_B_gen_power_max_14 : 0;
SIG_VALTYPE_ 1294 Motor_B_mot_power_max_14 : 0;
SIG_VALTYPE_ 1358 dc_link_vol_precharge_dmd_14 : 0;
SIG_VALTYPE_ 1358 system_time_stamp_14 : 0;
